# STM32H7B0x register map
File version: 1.3
CPU: CM7 r0p1, little endian, MPU, FPU, 4 interrupt priority bits
Registers are 32-bit, read-write, reset 0x0 unless marked. A register's access mark holds for its fields unless they carry their own. Offsets are from the block's base; [hi:lo] are bit positions; {n}, {i} and the like mark numbered series.

## RCC (part 2 of 3) — Reset and clock control
Base 0x58024400
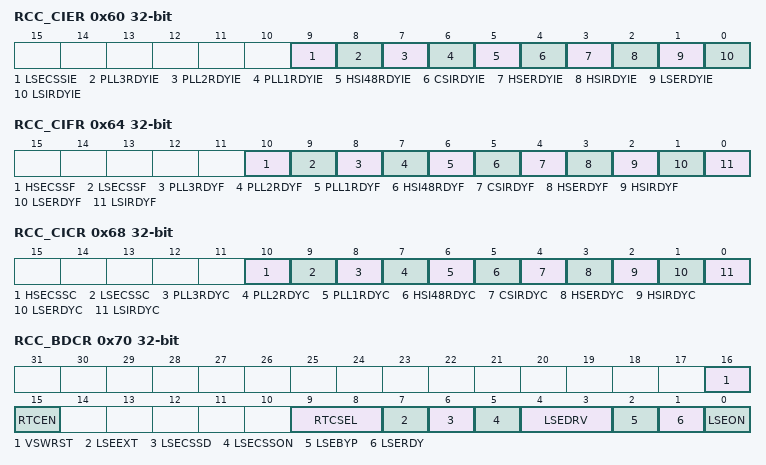
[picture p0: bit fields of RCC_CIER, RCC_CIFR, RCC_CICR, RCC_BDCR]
0x60 RCC_CIER
  [9] LSECSSIE — LSE clock security system interrupt enable Set and reset by software to enable/disable interrupt caused by the clock security system (CSS) on external 32 kHz oscillator.
    0=LSE CSS interrupt disabled (default after reset); 1=LSE CSS interrupt enabled
  [8] PLL3RDYIE — PLL3 ready interrupt enable Set and reset by software to enable/disable interrupt caused by PLL3 lock.
    0=PLL3 lock interrupt disabled (default after reset); 1=PLL3 lock interrupt enabled
  [7] PLL2RDYIE — PLL2 ready interrupt enable Set and reset by software to enable/disable interrupt caused by PLL2 lock.
    0=PLL2 lock interrupt disabled (default after reset); 1=PLL2 lock interrupt enabled
  [6] PLL1RDYIE — PLL1 ready interrupt enable Set and reset by software to enable/disable interrupt caused by PLL1 lock.
    0=PLL1 lock interrupt disabled (default after reset); 1=PLL1 lock interrupt enabled
  [5] HSI48RDYIE — HSI48 ready interrupt enable Set and reset by software to enable/disable interrupt caused by the HSI48 oscillator stabilization.
    0=HSI48 ready interrupt disabled (default after reset); 1=HSI48 ready interrupt enabled
  [4] CSIRDYIE — CSI ready interrupt enable Set and reset by software to enable/disable interrupt caused by the CSI oscillator stabilization.
    0=CSI ready interrupt disabled (default after reset); 1=CSI ready interrupt enabled
  [3] HSERDYIE — HSE ready interrupt enable Set and reset by software to enable/disable interrupt caused by the HSE oscillator stabilization.
    0=HSE ready interrupt disabled (default after reset); 1=HSE ready interrupt enabled
  [2] HSIRDYIE — HSI ready interrupt enable Set and reset by software to enable/disable interrupt caused by the HSI oscillator stabilization.
    0=HSI ready interrupt disabled (default after reset); 1=HSI ready interrupt enabled
  [1] LSERDYIE — LSE ready interrupt enable Set and reset by software to enable/disable interrupt caused by the LSE oscillator stabilization.
    0=LSE ready interrupt disabled (default after reset); 1=LSE ready interrupt enabled
  [0] LSIRDYIE — LSI ready interrupt enable Set and reset by software to enable/disable interrupt caused by the LSI oscillator stabilization.
    0=LSI ready interrupt disabled (default after reset); 1=LSI ready interrupt enabled
0x64 RCC_CIFR ro
  [10] HSECSSF — HSE clock security system interrupt flag Reset by software by writing HSECSSC bit. Set by hardware in case of HSE clock failure.
    0=no clock security interrupt caused by HSE clock failure (default after reset); 1=clock security interrupt caused by HSE clock failure
  [9] LSECSSF — LSE clock security system interrupt flag Reset by software by writing LSECSSC bit. Set by hardware when a failure is detected on the external 32 kHz oscillator and LSECSSIE is set.
    0=no failure detected on the external 32 kHz oscillator (default after reset); 1=failure detected on the external 32 kHz oscillator
  [8] PLL3RDYF — PLL3 ready interrupt flag Reset by software by writing PLL3RDYC bit. Set by hardware when the PLL3 locks and PLL3RDYIE is set.
    0=no clock ready interrupt caused by PLL3 lock (default after reset); 1=clock ready interrupt caused by PLL3 lock
  [7] PLL2RDYF — PLL2 ready interrupt flag Reset by software by writing PLL2RDYC bit. Set by hardware when the PLL2 locks and PLL2RDYIE is set.
    0=no clock ready interrupt caused by PLL2 lock (default after reset); 1=clock ready interrupt caused by PLL2 lock
  [6] PLL1RDYF — PLL1 ready interrupt flag Reset by software by writing PLL1RDYC bit. Set by hardware when the PLL1 locks and PLL1RDYIE is set.
    0=no clock ready interrupt caused by PLL1 lock (default after reset); 1=clock ready interrupt caused by PLL1 lock
  [5] HSI48RDYF — HSI48 ready interrupt flag Reset by software by writing HSI48RDYC bit. Set by hardware when the HSI48 clock becomes stable and HSI48RDYIE is set.
    0=no clock ready interrupt caused by the HSI48 oscillator (default after reset); 1=clock ready interrupt caused by the HSI48 oscillator
  [4] CSIRDYF — CSI ready interrupt flag Reset by software by writing CSIRDYC bit. Set by hardware when the CSI clock becomes stable and CSIRDYIE is set.
    0=no clock ready interrupt caused by the CSI (default after reset); 1=clock ready interrupt caused by the CSI
  [3] HSERDYF — HSE ready interrupt flag Reset by software by writing HSERDYC bit. Set by hardware when the HSE clock becomes stable and HSERDYIE is set.
    0=no clock ready interrupt caused by the HSE (default after reset); 1=clock ready interrupt caused by the HSE
  [2] HSIRDYF — HSI ready interrupt flag Reset by software by writing HSIRDYC bit. Set by hardware when the HSI clock becomes stable and HSIRDYIE is set.
    0=no clock ready interrupt caused by the HSI (default after reset); 1=clock ready interrupt caused by the HSI
  [1] LSERDYF — LSE ready interrupt flag Reset by software by writing LSERDYC bit. Set by hardware when the LSE clock becomes stable and LSERDYIE is set.
    0=no clock ready interrupt caused by the LSE (default after reset); 1=clock ready interrupt caused by the LSE
  [0] LSIRDYF — LSI ready interrupt flag Reset by software by writing LSIRDYC bit. Set by hardware when the LSI clock becomes stable and LSIRDYIE is set.
    0=no clock ready interrupt caused by the LSI (default after reset); 1=clock ready interrupt caused by the LSI
0x68 RCC_CICR
  [10] HSECSSC — HSE clock security system interrupt clear Set by software to clear HSECSSF. Reset by hardware when clear done.
    0=HSECSSF no effect (default after reset); 1=HSECSSF cleared
  [9] LSECSSC — LSE clock security system interrupt clear Set by software to clear LSECSSF. Reset by hardware when clear done.
    0=LSECSSF no effect (default after reset); 1=LSECSSF cleared
  [8] PLL3RDYC — PLL3 ready interrupt clear Set by software to clear PLL3RDYF. Reset by hardware when clear done.
    0=PLL3RDYF no effect (default after reset); 1=PLL3RDYF cleared
  [7] PLL2RDYC — PLL2 ready interrupt clear Set by software to clear PLL2RDYF. Reset by hardware when clear done.
    0=PLL2RDYF no effect (default after reset); 1=PLL2RDYF cleared
  [6] PLL1RDYC — PLL1 ready interrupt clear Set by software to clear PLL1RDYF. Reset by hardware when clear done.
    0=PLL1RDYF no effect (default after reset); 1=PLL1RDYF cleared
  [5] HSI48RDYC — HSI48 ready interrupt clear Set by software to clear HSI48RDYF. Reset by hardware when clear done.
    0=HSI48RDYF no effect (default after reset); 1=HSI48RDYF cleared
  [4] CSIRDYC — CSI ready interrupt clear Set by software to clear CSIRDYF. Reset by hardware when clear done.
    0=CSIRDYF no effect (default after reset); 1=CSIRDYF cleared
  [3] HSERDYC — HSE ready interrupt clear Set by software to clear HSERDYF. Reset by hardware when clear done.
    0=HSERDYF no effect (default after reset); 1=HSERDYF cleared
  [2] HSIRDYC — HSI ready interrupt clear Set by software to clear HSIRDYF. Reset by hardware when clear done.
    0=HSIRDYF no effect (default after reset); 1=HSIRDYF cleared
  [1] LSERDYC — LSE ready interrupt clear Set by software to clear LSERDYF. Reset by hardware when clear done.
    0=LSERDYF no effect (default after reset); 1=LSERDYF cleared
  [0] LSIRDYC — LSI ready interrupt clear Set by software to clear LSIRDYF. Reset by hardware when clear done.
    0=LSIRDYF no effect (default after reset); 1=LSIRDYF cleared
0x70 RCC_BDCR access per field — RCC Backup domain control register
  [16] VSWRST rw — VSwitch domain software reset Set and reset by software.
    0=reset not activated (default after Backup domain reset); 1=resets the entire VSW domain
  [15] RTCEN rw — RTC clock enable Set and reset by software.
    0=rtc_ck disabled (default after Backup domain reset); 1=rtc_ck enabled
  [9:8] RTCSEL rw-once — RTC clock source selection Set by software to select the clock source for the RTC. These bits can be written only one time (except in case of failure detection on LSE). These bits must be written before LSECSSON is enabled. The VSWRST bit can be used to reset them, then it can be written one time again. If HSE is selected as RTC clock, this clock is lost when the system is in Stop mode or in case of a pin reset (NRST).
    0=no clock (default after Backup domain reset); 1=LSE selected as RTC clock; 2=LSI selected as RTC clock; 3=HSE divided by RTCPRE value selected as RTC clock
  [7] LSEEXT rw — low-speed external clock type in Bypass mode Set and reset by software to select the external clock type (analog or digital). The external clock must be enabled with the LSEON bit, to be used by the device. The LSEEXT bit can be written only if the LSE oscillator is disabled.
    0=LSE in analog mode (default after Backup domain reset); 1=LSE in digital mode (do not use if RTC is active)
  [6] LSECSSD ro — LSE clock security system failure detection Set by hardware to indicate when a failure has been detected by the clock security system on the external 32 kHz oscillator.
    0=no failure detected on 32 kHz oscillator (default after Backup domain reset); 1=failure detected on 32 kHz oscillator
  [5] LSECSSON rw — LSE clock security system enable Set by software to enable the clock security system on 32 kHz oscillator. LSECSSON must be enabled after LSE is enabled (LSEON enabled) and ready (LSERDY set by hardware) and after RTCSEL is selected. Once enabled, this bit cannot be disabled, except after a LSE failure detection (LSECSSD = 1). In that case the software must disable LSECSSON.
    0=CSS on 32 kHz oscillator OFF (default after Backup domain reset); 1=CSS on 32 kHz oscillator ON
  [4:3] LSEDRV rw — LSE oscillator driving capability Set by software to select the driving capability of the LSE oscillator.
    0=lowest drive (default after Backup domain reset); 1=medium-low drive; 2=medium-high drive; 3=highest drive
  [2] LSEBYP rw — LSE oscillator bypass Set and reset by software to bypass oscillator in debug mode. This bit must not be written when the LSE is enabled (by LSEON) or ready (LSERDY = 1)
    0=LSE oscillator not bypassed (default after Backup domain reset); 1=LSE oscillator bypassed
  [1] LSERDY ro — LSE oscillator ready Set and reset by hardware to indicate when the LSE is stable. This bit needs 6 cycles of lse_ck clock to fall down after LSEON has been set to 0.
    0=LSE oscillator not ready (default after Backup domain reset); 1=LSE oscillator ready
  [0] LSEON rw — LSE oscillator enabled Set and reset by software.
    0=LSE oscillator OFF (default after Backup domain reset); 1=LSE oscillator ON
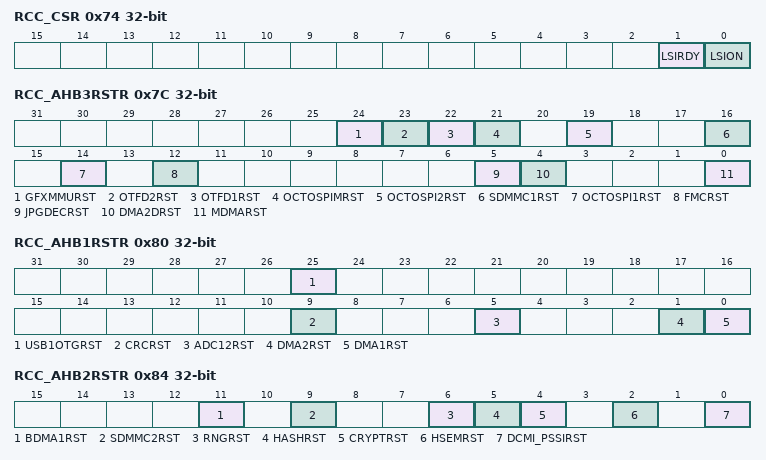
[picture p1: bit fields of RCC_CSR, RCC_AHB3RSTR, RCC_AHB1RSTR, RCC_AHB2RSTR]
0x74 RCC_CSR access per field — RCC clock control and status register
  [1] LSIRDY ro — LSI oscillator ready Set and reset by hardware to indicate when the low-speed internal RC oscillator is stable. This bit needs 3 cycles of lsi_ck clock to fall down after LSION has been set to 0. This bit can be set even when LSION is not enabled if there is a request for LSI clock by the clock security system on LSE or by the low-speed watchdog or by the RTC.
    0=LSI clock is not ready (default after reset); 1=LSI clock is ready
  [0] LSION rw — LSI oscillator enable Set and reset by software.
    0=LSI is OFF (default after reset); 1=LSI is ON
0x7C RCC_AHB3RSTR
  [24] GFXMMURST — GFXMMU reset Set and reset by software
    0=does not reset the GFXMMU (default after reset); 1=resets the GFXMMU
  [23] OTFD2RST — OTFD2 reset Set and reset by software Take care that resetting the OTFD means loosing the decryption key loaded during secure boot.
    0=does not reset the OTFD2 (default after reset); 1=resets the OTFD2
  [22] OTFD1RST — OTFD1 reset Set and reset by software Take care that resetting the OTFD means loosing the decryption key loaded during secure boot.
    0=does not reset the OTFD1 (default after reset); 1=resets the OTFD1
  [21] OCTOSPIMRST — OCTOSPIM reset Set and reset by software
    0=does not reset the OCTOSPIM (default after reset); 1=resets the OCTOSPIM
  [19] OCTOSPI2RST — OCTOSPI2 and OCTOSPI2 delay block reset Set and reset by software
    0=does not reset the OCTOSPI2 and OCTOSPI2 delay block (default after reset); 1=resets the OCTOSPI2 and OCTOSPI2 delay block
  [16] SDMMC1RST — SDMMC1 and SDMMC1 delay blocks reset Set and reset by software.
    0=does not reset SDMMC1 and SDMMC1 delay blocks (default after reset); 1=resets SDMMC1 and SDMMC1 delay blocks
  [14] OCTOSPI1RST — OCTOSPI1 and OCTOSPI1 delay blocks reset Set and reset by software.
    0=does not reset OCTOSPI1 and OCTOSPI1 delay blocks (default after reset); 1=resets OCTOSPI1 and OCTOSPI1 delay blocks
  [12] FMCRST — FMC block reset Set and reset by software.
    0=does not reset FMC block (default after reset); 1=resets FMC block
  [5] JPGDECRST — JPGDEC block reset Set and reset by software.
    0=does not reset JPGDEC block (default after reset); 1=resets JPGDEC block
  [4] DMA2DRST — DMA2D block reset Set and reset by software.
    0=does not reset DMA2D block (default after reset); 1=resets DMA2D block
  [0] MDMARST — MDMA block reset Set and reset by software.
    0=does not reset MDMA block (default after reset); 1=resets MDMA block
0x80 RCC_AHB1RSTR
  [25] USB1OTGRST — USB1OTG block reset Set and reset by software.
    0=does not reset USB1OTG block (default after reset); 1=resets USB1OTG block
  [9] CRCRST — CRC block reset Set and reset by software.
    0=does not reset CRC block (default after reset); 1=resets CRC block
  [5] ADC12RST — ADC1 and 2 blocks reset Set and reset by software.
    0=does not reset ADC1 and 2 blocks (default after reset); 1=resets ADC1 and 2 blocks
  [1] DMA2RST — DMA2 and DMAMUX2 blocks reset Set and reset by software.
    0=does not reset DMA2 and DMAMUX2 blocks (default after reset); 1=resets DMA2 and DMAMUX2 blocks
  [0] DMA1RST — DMA1 and DMAMUX1 blocks reset Set and reset by software.
    0=does not reset DMA1 and DMAMUX1 blocks (default after reset); 1=resets DMA1 and DMAMUX1 blocks
0x84 RCC_AHB2RSTR
  [11] BDMA1RST — BDMA1 reset (DFSDM dedicated DMA) Set and reset by software.
    0=does not reset DMA block (default after reset); 1=resets DMA block
  [9] SDMMC2RST — SDMMC2 and SDMMC2 delay blocks reset Set and reset by software.
    0=does not reset SDMMC2 and SDMMC2 delay blocks (default after reset); 1=resets SDMMC2 and SDMMC2 delay blocks
  [6] RNGRST — random number generator block reset Set and reset by software.
    0=does not reset RNG block (default after reset); 1=resets RNG block
  [5] HASHRST — hash block reset Set and reset by software.
    0=does not reset hash block (default after reset); 1=resets hash block
  [4] CRYPTRST — cryptography block reset Set and reset by software.
    0=does not reset cryptography block (default after reset); 1=resets cryptography block
  [2] HSEMRST — HSEM block reset Set and reset by software.
    0=does not reset HSEM block (default after reset); 1=resets HSEM block
  [0] DCMI_PSSIRST — digital camera interface block reset (DCMI or PSSI depending which IP is active) Set and reset by software.
    0=does not reset the DCMI/PSSI block (default after reset); 1=resets the DCMI/PSSI block
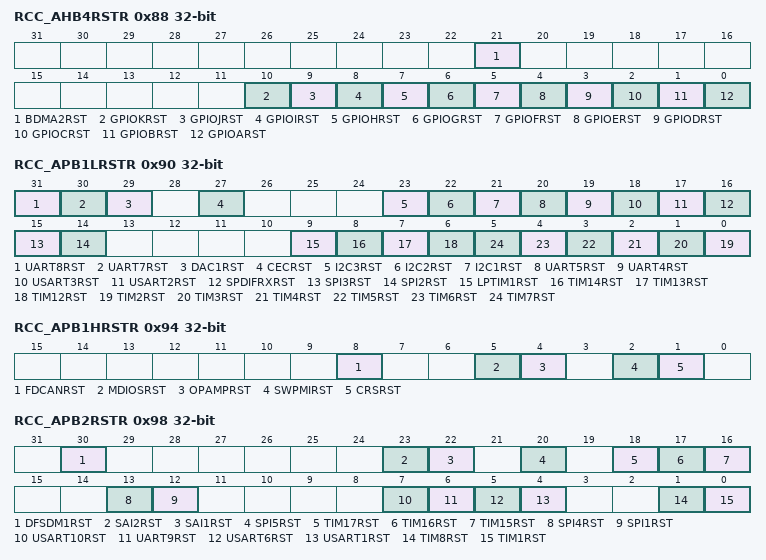
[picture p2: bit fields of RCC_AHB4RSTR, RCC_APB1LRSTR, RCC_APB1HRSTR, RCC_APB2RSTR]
0x88 RCC_AHB4RSTR
  [21] BDMA2RST — SmartRun domain DMA and DMAMUX blocks reset Set and reset by software.
    0=does not reset the DMA and DMAMUX blocks (default after reset); 1=resets the DMA and DMAMUX blocks
  [10] GPIOKRST — GPIOK block reset Set and reset by software.
    0=does not reset the GPIOK block (default after reset); 1=resets the GPIOK block
  [9] GPIOJRST — GPIOJ block reset Set and reset by software.
    0=does not reset the GPIOJ block (default after reset); 1=resets the GPIOJ block
  [8] GPIOIRST — GPIOI block reset Set and reset by software.
    0=does not reset the GPIOI block (default after reset); 1=resets the GPIOI block
  [7] GPIOHRST — GPIOH block reset Set and reset by software.
    0=does not reset the GPIOH block (default after reset); 1=resets the GPIOH block
  [6] GPIOGRST — GPIOG block reset Set and reset by software.
    0=does not reset the GPIOG block (default after reset); 1=resets the GPIOG block
  [5] GPIOFRST — GPIOF block reset Set and reset by software.
    0=does not reset the GPIOF block (default after reset); 1=resets the GPIOF block
  [4] GPIOERST — GPIOE block reset Set and reset by software.
    0=does not reset the GPIOE block (default after reset); 1=resets the GPIOE block
  [3] GPIODRST — GPIOD block reset Set and reset by software.
    0=does not reset the GPIOD block (default after reset); 1=resets the GPIOD block
  [2] GPIOCRST — GPIOC block reset Set and reset by software.
    0=does not reset the GPIOC block (default after reset); 1=resets the GPIOC block
  [1] GPIOBRST — GPIOB block reset Set and reset by software.
    0=does not reset the GPIOB block (default after reset); 1=resets the GPIOB block
  [0] GPIOARST — GPIOA block reset Set and reset by software.
    0=does not reset the GPIOA block (default after reset); 1=resets the GPIOA block
0x8C RCC_APB3RSTR
  [3] LTDCRST — LTDC block reset Set and reset by software.
    0=does not reset the LTDC block (default after reset); 1=resets the LTDC block
0x90 RCC_APB1LRSTR
  [31] UART8RST — UART8 block reset Set and reset by software.
    0=does not reset the UART8 block (default after reset); 1=resets the UART8 block
  [30] UART7RST — UART7 block reset Set and reset by software.
    0=does not reset the UART7 block (default after reset); 1=resets the UART7 block
  [29] DAC1RST — DAC1 (containing two converters) reset Set and reset by software.
    0=does not reset the DAC1 (default after reset); 1=resets the DAC1
  [27] CECRST — HDMI-CEC block reset Set and reset by software.
    0=does not reset the HDMI-CEC block (default after reset); 1=resets the HDMI-CEC block
  [23] I2C3RST — I2C3 block reset Set and reset by software.
    0=does not reset the I2C3 block (default after reset); 1=resets the I2C3 block
  [22] I2C2RST — I2C2 block reset Set and reset by software.
    0=does not reset the I2C2 block (default after reset); 1=resets the I2C2 block
  [21] I2C1RST — I2C1 block reset Set and reset by software.
    0=does not reset the I2C1 block (default after reset); 1=resets the I2C1 block
  [20] UART5RST — UART5 block reset Set and reset by software.
    0=does not reset the UART5 block (default after reset); 1=resets the UART5 block
  [19] UART4RST — UART4 block reset Set and reset by software.
    0=does not reset the UART4 block (default after reset); 1=resets the UART4 block
  [18] USART3RST — USART3 block reset Set and reset by software.
    0=does not reset the USART3 block (default after reset); 1=resets the USART3 block
  [17] USART2RST — USART2 block reset Set and reset by software.
    0=does not reset the USART2 block (default after reset); 1=resets the USART2 block
  [16] SPDIFRXRST — SPDIFRX block reset Set and reset by software.
    0=does not reset the SPDIFRX block (default after reset); 1=resets the SPDIFRX block
  [15] SPI3RST — SPI3 block reset Set and reset by software.
    0=does not reset the SPI3 block (default after reset); 1=resets the SPI3 block
  [14] SPI2RST — SPI2 block reset Set and reset by software.
    0=does not reset the SPI2 block (default after reset); 1=resets the SPI2 block
  [9] LPTIM1RST — LPTIM1 block reset Set and reset by software.
    0=does not reset the LPTIM1 block (default after reset); 1=resets the LPTIM1 block
  [8] TIM14RST — TIM14 block reset Set and reset by software.
    0=does not reset the TIM14 block (default after reset); 1=resets the TIM14 block
  [7] TIM13RST — TIM13 block reset Set and reset by software.
    0=does not reset the TIM13 block (default after reset); 1=resets the TIM13 block
  [6] TIM12RST — TIM12 block reset Set and reset by software.
    0=does not reset the TIM12 block (default after reset); 1=resets the TIM12 block
  [n-2] TIM{n}RST (n=2..7) — TIM{n} block reset Set and reset by software.
    0=does not reset the TIM{n} block (default after reset); 1=resets the TIM{n} block
0x94 RCC_APB1HRSTR
  [8] FDCANRST — FDCAN block reset Set and reset by software.
    0=does not reset the FDCAN block (default after reset); 1=resets the FDCAN block
  [5] MDIOSRST — MDIOS block reset Set and reset by software.
    0=does not reset the MDIOS block (default after reset); 1=resets the MDIOS block
  [4] OPAMPRST — OPAMP block reset Set and reset by software.
    0=does not reset the OPAMP block (default after reset); 1=resets the OPAMP block
  [2] SWPMIRST — SWPMI block reset Set and reset by software.
    0=does not reset the SWPMI block (default after reset); 1=resets the SWPMI block
  [1] CRSRST — clock recovery system reset Set and reset by software.
    0=does not reset CRS (default after reset); 1=resets CRS
0x98 RCC_APB2RSTR
  [30] DFSDM1RST — DFSDM1 block reset Set and reset by software.
    0=does not reset DFSDM1 block (default after reset); 1=resets DFSDM1 block
  [23] SAI2RST — SAI2 block reset Set and reset by software.
    0=does not reset the SAI2 block (default after reset); 1=resets the SAI2 block
  [22] SAI1RST — SAI1 block reset Set and reset by software.
    0=does not reset the SAI1 (default after reset); 1=resets the SAI1
  [20] SPI5RST — SPI5 block reset Set and reset by software.
    0=does not reset the SPI5 block (default after reset); 1=resets the SPI5 block
  [18] TIM17RST — TIM17 block reset Set and reset by software.
    0=does not reset the TIM17 block (default after reset); 1=resets the TIM17 block
  [17] TIM16RST — TIM16 block reset Set and reset by software.
    0=does not reset the TIM16 block (default after reset); 1=resets the TIM16 block
  [16] TIM15RST — TIM15 block reset Set and reset by software.
    0=does not reset the TIM15 block (default after reset); 1=resets the TIM15 block
  [13] SPI4RST — SPI4 block reset Set and reset by software.
    0=does not reset the SPI4 block (default after reset); 1=resets the SPI4 block
  [12] SPI1RST — SPI1 block reset Set and reset by software.
    0=does not reset the SPI1 block (default after reset); 1=resets the SPI1 block
  [7] USART10RST — USART10 block reset Set and reset by software.
    0=does not reset the USART10 block (default after reset); 1=resets the USART10 block
  [6] UART9RST — UART9 block reset Set and reset by software.
    0=does not reset the UART9 block (default after reset); 1=resets the UART9 block
  [5] USART6RST — USART6 block reset Set and reset by software.
    0=does not reset the USART6 block (default after reset); 1=resets the USART6 block
  [4] USART1RST — USART1 block reset Set and reset by software.
    0=does not reset the USART1 block (default after reset); 1=resets the USART1 block
  [1] TIM8RST — TIM8 block reset Set and reset by software.
    0=does not reset the TIM8 block (default after reset); 1=resets the TIM8 block
  [0] TIM1RST — TIM1 block reset Set and reset by software.
    0=does not reset the TIM1 block (default after reset); 1=resets the TIM1 block
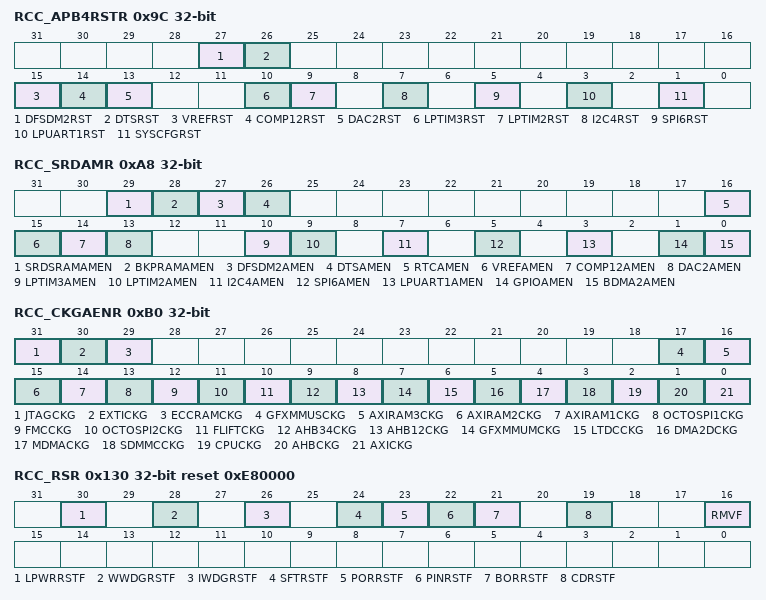
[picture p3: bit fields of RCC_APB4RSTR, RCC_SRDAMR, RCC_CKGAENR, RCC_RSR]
0x9C RCC_APB4RSTR
  [27] DFSDM2RST — DFSDM2 block reset Set and reset by software.
    0=does not reset the DFSDM2 block (default after reset); 1=resets the DFSDM2 block
  [26] DTSRST — Digital temperature sensor block reset Set and reset by software.
    0=does not reset the DTS block (default after reset); 1=resets the DTS block
  [15] VREFRST — VREF block reset Set and reset by software.
    0=does not reset the VREF block (default after reset); 1=resets the VREF block
  [14] COMP12RST — COMP1 and 2 blocks reset Set and reset by software.
    0=does not reset the COMP1 and 2 blocks (default after reset); 1=resets the COMP1 and 2 blocks
  [13] DAC2RST — DAC2 (containing one converter) reset Set and reset by software.
    0=does not reset the DAC2 (default after reset); 1=resets the DAC2
  [10] LPTIM3RST — LPTIM3 block reset Set and reset by software.
    0=does not reset the LPTIM3 block (default after reset); 1=resets the LPTIM3 block
  [9] LPTIM2RST — LPTIM2 block reset Set and reset by software.
    0=does not reset the LPTIM2 block (default after reset); 1=resets the LPTIM2 block
  [7] I2C4RST — I2C4 block reset Set and reset by software.
    0=does not reset the I2C4 block (default after reset); 1=resets the I2C4 block
  [5] SPI6RST — SPI6 block reset Set and reset by software.
    0=does not reset the SPI6 block (default after reset); 1=resets the SPI6 block
  [3] LPUART1RST — LPUART1 block reset Set and reset by software.
    0=does not reset the LPUART1 block (default after reset); 1=resets the LPUART1 block
  [1] SYSCFGRST — SYSCFG block reset Set and reset by software.
    0=does not reset the SYSCFG block (default after reset); 1=resets the SYSCFG block
0xA8 RCC_SRDAMR — RCC SmartRun domain Autonomous mode register
  [29] SRDSRAMAMEN — SmartRun domain SRAM Autonomous mode enable Set and reset by software. Refer to for additional information.
    0=SRDSRAM clock disabled when the CPU is in CStop (default after reset); 1=SRDSRAM bus clock enabled when the SmartRun domain is in Run
  [28] BKPRAMAMEN — Backup RAM Autonomous mode enable Set and reset by software. Refer to for additional information.
    0=Backup RAM clock disabled when the CPU is in CStop (default after reset); 1=Backup RAM clock enabling is controlled by the SmartRun domain state
  [27] DFSDM2AMEN — DFSDM2 Autonomous mode enable Set and reset by software. Refer to for additional information.
    0=DFSDM2 clock disabled when the CPU is in CStop (default after reset); 1=DFSDM2 peripheral clocks enabled when the SmartRun domain is in Run mode. Kernel clock enabled when the SmartRun domain is in Stop mode.
  [26] DTSAMEN — Digital temperature sensor Autonomous mode enable Set and reset by software. Refer to for additional information.
    0=DTS clocks disabled when the CPU is in CStop (default after reset); 1=DTS clocks enabled when the SmartRun domain is in Run
  [16] RTCAMEN — RTC Autonomous mode enable Set and reset by software. Refer to for additional information.
    0=RTC bus clocks disabled when the CPU is in CStop (default after reset); 1=RTC bus clocks enabled when the SmartRun domain is in Run
  [15] VREFAMEN — VREF Autonomous mode enable Set and reset by software. Refer to for additional information.
    0=VREF clocks disabled when the CPU is in CStop (default after reset); 1=VREF clocks enabled when the SmartRun domain is in Run or Stop mode
  [14] COMP12AMEN — COMP1 and 2 Autonomous mode enable Set and reset by software. Refer to for additional information.
    0=COMP1 and 2 peripheral clocks disabled when the CPU is in CStop (default after reset); 1=COMP1 and 2 peripheral clocks enabled when the SmartRun domain is in Run
  [13] DAC2AMEN — DAC2 (containing one converter) Autonomous mode enable Set and reset by software. Refer to for additional information.
    0=DAC2 peripheral clocks disabled when the CPU is in CStop (default after reset); 1=DAC2 peripheral clocks enabled when the SmartRun domain is in Run
  [10] LPTIM3AMEN — LPTIM3 Autonomous mode enable Set and reset by software. Refer to for additional information.
    0=LPTIM3 peripheral clocks disabled when the CPU is in CStop (default after reset); 1=LPTIM3 peripheral clocks enabled when the SmartRun domain is in Run mode. Kernel clock is enabled when the SmartRun domain is in Stop mode.
  [9] LPTIM2AMEN — LPTIM2 Autonomous mode enable Set and reset by software. Refer to for additional information
    0=LPTIM2 peripheral clocks are disabled when the CPU is in CStop (default after reset); 1=LPTIM2 peripheral clocks enabled when the SmartRun domain is in Run mode. Kernel clock is enabled when the SmartRun domain is in Stop mode.
  [7] I2C4AMEN — I2C4 Autonomous mode enable Set and reset by software. Refer to for additional information.
    0=I2C4 peripheral clocks disabled when the CPU is in CStop (default after reset); 1=I2C4 peripheral clocks enabled when the SmartRun domain is in Run mode. Kernel clock is enabled when the SmartRun domain is in Stop mode.
  [5] SPI6AMEN — SPI6 Autonomous mode enable Set and reset by software. Refer to for additional information.
    0=SPI6 peripheral clocks disabled when the CPU is in CStop (default after reset); 1=SPI6 peripheral clocks enabled when the SmartRun domain is in Run mode. Kernel clock is enabled when the SmartRun domain is in Stop mode.
  [3] LPUART1AMEN — LPUART1 Autonomous mode enable Set and reset by software. Refer to for additional information.
    0=LPUART1 peripheral clocks disabled when the CPU is in CStop (default after reset); 1=LPUART1 peripheral clocks enabled when the SmartRun domain is in Run mode. Kernel clock is enabled when the SmartRun domain is in Stop mode.
  [1] GPIOAMEN — GPIO Autonomous mode enable Set and reset by software. Refer to for additional information.
    0=GPIO peripheral clocks disabled when the CPU is in CStop (default after reset); 1=GPIO peripheral clocks enabled when the SmartRun domain is in Run
  [0] BDMA2AMEN — SmartRun domain DMA and DMAMUX Autonomous mode enable Set and reset by software. Refer to for additional information.
    0=BDMA2 and DMAMUX2 peripheral clocks disabled when the CPU is in CStop (default after reset); 1=BDMA2 and DMAMUX2 peripheral clocks enabled when the SmartRun domain is in Run
0xB0 RCC_CKGAENR — RCC AXI clocks gating enable register
  [31] JTAGCKG — JTAG automatic clock gating This bit is set and reset by software.
    0=The clock gating is disabled. The clock is always enabled.; 1=The clock gating is enabled. The clock is disabled except if a JTAG connection has been detected
  [30] EXTICKG — EXTI clock gating This bit is set and reset by software.
    0=The clock gating is disabled. The clock is always enabled.; 1=The clock gating is enabled. The clock is enabled after an event detection and stopped again when the event flag is cleared.
  [29] ECCRAMCKG — RAM error code correction (ECC) clock gating This bit is set and reset by software.
    0=The clock gating is disabled. The clock is always enabled.; 1=The clock gating is enabled. The ECC clock is enabled only during a RAM access.
  [17] GFXMMUSCKG — AXI matrix slave GFXMMU clock gating This bit is set and reset by software.
    0=The clock gating is disabled. The clock is always enabled; 1=The clock gating is enabled. The AXI matrix slave GFXMMU clock is enabled on bus transaction request.
  [16] AXIRAM3CKG — AXI matrix slave SRAM3 clock gating This bit is set and reset by software.
    0=The clock gating is disabled. The clock is always enabled.; 1=The clock gating is enabled. The AXI matrix slave SRAM3 clock is enabled on bus transaction request.
  [15] AXIRAM2CKG — AXI matrix slave SRAM2 clock gating This bit is set and reset by software.
    0=The clock gating is disabled. The clock is always enabled.; 1=The clock gating is enabled. The AXI matrix slave SRAM2 clock is enabled on bus transaction request.
  [14] AXIRAM1CKG — AXI slave SRAM1 clock gating This bit is set and reset by software.
    0=The clock gating is disabled. The clock is always enabled.; 1=The clock gating is enabled. The AXI matrix slave SRAM1 clock is enabled on bus transaction request.
  [13] OCTOSPI1CKG — AXI slave OCTOSPI1 clock gating This bit is set and reset by software.
    0=The clock gating is disabled. The clock is always enabled.; 1=The clock gating is enabled. The AXI matrix slave OCTOSPI1 clock is enabled on bus transaction request.
  [12] FMCCKG — AXI slave FMC clock gating This bit is set and reset by software.
    0=The clock gating is disabled. The clock is always enabled.; 1=The clock gating is enabled. The AXI matrix slave FMC clock is enabled on bus transaction request.
  [11] OCTOSPI2CKG — AXI slave OCTOSPI2 clock gating This bit is set and reset by software.
    0=The clock gating is disabled. The clock is always enabled.; 1=The clock gating is enabled. The AXI matrix slave OCTOSPI2 clock is enabled on bus transaction request.
  [10] FLIFTCKG — AXI slave Flash interface (FLIFT) clock gating This bit is set and reset by software.
    0=The clock gating is disabled. The clock is always enabled.; 1=The clock gating is enabled. The AXI matrix slave FLIFT clock is enabled on bus transaction request.
  [9] AHB34CKG — AXI slave AHB34 clock gating This bit is set and reset by software.
    0=The clock gating is disabled. The clock is always enabled; 1=The clock gating is enabled. The AXI matrix slave AHB34 clock is enabled on bus transaction request.
  [8] AHB12CKG — AXI slave AHB12 clock gating This bit is set and reset by software.
    0=The clock gating is disabled. The clock is always enabled; 1=The clock gating is enabled. The AXI matrix slave AHB12 clock is enabled on bus transaction request.
  [7] GFXMMUMCKG — AXI master GFXMMU clock gating This bit is set and reset by software.
    0=The clock gating is disabled. The clock is always enabled; 1=The clock gating is enabled. The AXI matrix master GFXMMU clock is enabled on bus transaction request.
  [6] LTDCCKG — AXI master LTDC clock gating This bit is set and reset by software.
    0=The clock gating is disabled. The clock is always enabled.; 1=The clock gating is enabled. The AXI matrix master LTDC clock is enabled on bus transaction request.
  [5] DMA2DCKG — AXI master DMA2D clock gating This bit is set and reset by software.
    0=The clock gating is disabled. The clock is always enabled; 1=The clock gating is enabled. The AXI matrix master DMA2D clock is enabled on bus transaction request.
  [4] MDMACKG — AXI master MDMA clock gating This bit is set and reset by software.
    0=The clock gating is disabled. The clock is always enabled; 1=The clock gating is enabled. The AXI matrix master MDMA clock is enabled on bus transaction request.
  [3] SDMMCCKG — AXI master SDMMC clock gating This bit is set and reset by software.
    0=The clock gating is disabled. The clock is always enabled.; 1=The clock gating is enabled. The AXI matrix master SDMMC clock is enabled on bus transaction request.
  [2] CPUCKG — AXI master CPU clock gating This bit is set and reset by software.
    0=The clock gating is disabled. The clock is always enabled.; 1=The clock gating is enabled. The AXI matrix master CPU clock is enabled on bus transaction request.
  [1] AHBCKG — AXI master AHB clock gating This bit is set and reset by software.
    0=The clock gating is disabled. The clock is always enabled.; 1=The clock gating is enabled. The AXI matrix master AHB clock is enabled on bus transaction request.
  [0] AXICKG — AXI interconnect matrix clock gating This bit is set and reset by software.
    0=The clock gating is disabled. The clock is always enabled; 1=The clock gating is enabled. The AXI interconnect matrix clock is enabled on bus transaction request.
0x130 RCC_RSR access per field reset 0xE80000 — RCC reset status register
  [30] LPWRRSTF ro — reset due to illegal CD DStop or CD DStop2 or CPU CStop flag Reset by software by writing the RMVF bit. Set by hardware when the CPU domain goes erroneously in DStop or DStop2, or when the CPU goes erroneously in CStop.
    0=no illegal reset occurred (default after power-on reset); 1=illegal CD DStop or CD DStop2 or CPU CStop reset occurred
  [28] WWDGRSTF ro — window watchdog reset flag Reset by software by writing the RMVF bit. Set by hardware when a window watchdog reset occurs.
    0=no window watchdog reset occurred from WWDG (default after power-on reset); 1=window watchdog reset occurred from WWDG
  [26] IWDGRSTF ro — independent watchdog reset flag Reset by software by writing the RMVF bit. Set by hardware when an independent watchdog reset occurs.
    0=no independent watchdog reset occurred (default after power-on reset); 1=independent watchdog reset occurred
  [24] SFTRSTF ro — system reset from CPU reset flag Reset by software by writing the RMVF bit. Set by hardware when the system reset is due to CPU.The CPU can generate a system reset by writing SYSRESETREQ bit of AIRCR register of the core M7.
    0=no CPU software reset occurred (default after power-on reset); 1=a system reset has been generated by the CPU
  [23] PORRSTF ro — POR/PDR reset flag Reset by software by writing the RMVF bit. Set by hardware when a POR/PDR reset occurs.
    0=no POR/PDR reset occurred; 1=POR/PDR reset occurred (default after power-on reset)
  [22] PINRSTF ro — pin reset flag (NRST) Reset by software by writing the RMVF bit. Set by hardware when a reset from pin occurs.
    0=no reset from pin occurred; 1=reset from pin occurred (default after power-on reset)
  [21] BORRSTF ro — BOR reset flag Reset by software by writing the RMVF bit. Set by hardware when a BOR reset occurs (pwr_bor_rst).
    0=no BOR reset occurred; 1=BOR reset occurred (default after power-on reset)
  [19] CDRSTF ro — CPU domain power-switch reset flag Reset by software by writing the RMVF bit. Set by hardware when a the CPU domain exits from DStop or after of power-on reset. Set also when the CPU domain exists DStop2 but only when a pad reset has occurred during DStop2 (PINRST bit also set by hardware)
    0=no CPU domain power-switch reset occurred; 1=CPU domain power-switch (ePOD2) reset occurred (default after power-on reset)
  [16] RMVF rw — remove reset flag Set and reset by software to reset the value of the reset flags.
    0=reset of the reset flags not activated (default after power-on reset); 1=resets the value of the reset flags
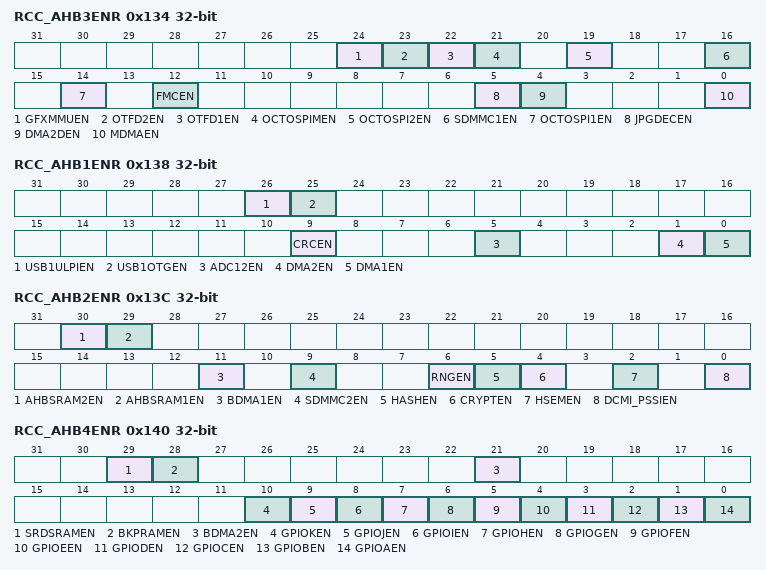
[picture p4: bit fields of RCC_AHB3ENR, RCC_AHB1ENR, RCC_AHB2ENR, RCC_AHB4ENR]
0x134 RCC_AHB3ENR
  [24] GFXMMUEN — GFXMMU clock enable Set and reset by software.
    0=GFXMMU clock disabled (default after reset); 1=GFXMMU clock enabled
  [23] OTFD2EN — OTFD2 clock enable Set and reset by software.
    0=OTFD2 clock disabled (default after reset); 1=OTFD2 clock enabled
  [22] OTFD1EN — OTFD1 clock enable Set and reset by software.
    0=OTFD1 clock disabled (default after reset); 1=OTFD1 clock enabled
  [21] OCTOSPIMEN — OCTOSPIM clock enable Set and reset by software.
    0=OCTOSPIM clock disabled (default after reset); 1=OCTOSPIM clock enabled
  [19] OCTOSPI2EN — OCTOSPI2 clock enable Set and reset by software.
    0=OCTOSPI2 and OCTOSPI2 delay clock disabled (default after reset); 1=OCTOSPI2 OCTOSPI2 delay clock enabled
  [16] SDMMC1EN — SDMMC1 and SDMMC1 delay clock enable Set and reset by software.
    0=SDMMC1 and SDMMC1 delay clock disabled (default after reset); 1=SDMMC1 and SDMMC1 delay clock enabled
  [14] OCTOSPI1EN — OCTOSPI1 and OCTOSPI1 delay clock enable Set and reset by software.
    0=OCTOSPI1 and OCTOSPI1 delay clock disabled (default after reset); 1=OCTOSPI1 and OCTOSPI1 delay clock enabled
  [12] FMCEN — FMC peripheral clocks enable Set and reset by software. The peripheral clocks of the FMC are the kernel clock selected by FMCSEL and provided to fmc_ker_ck input, and the rcc_hclk3 bus interface clock.
    0=FMC peripheral clocks disabled (default after reset); 1=FMC peripheral clocks enabled
  [5] JPGDECEN — JPGDEC peripheral clock enable Set and reset by software.
    0=JPGDEC peripheral clock disabled (default after reset); 1=JPGDEC peripheral clock enabled
  [4] DMA2DEN — DMA2D peripheral clock enable Set and reset by software.
    0=DMA2D peripheral clock disabled (default after reset); 1=DMA2D peripheral clock enabled
  [0] MDMAEN — MDMA peripheral clock enable Set and reset by software.
    0=MDMA peripheral clock disabled (default after reset); 1=MDMA peripheral clock enabled
0x138 RCC_AHB1ENR
  [26] USB1ULPIEN — USB_PHY1 clocks enable Set and reset by software.
    0=USB1ULPI PHY clocks disabled (default after reset); 1=USB1ULPI PHY clocks enabled
  [25] USB1OTGEN — USB1OTG peripheral clocks enable Set and reset by software. The peripheral clocks of the USB1OTG are the kernel clock selected by USBSEL and the rcc_hclk1 bus interface clock.
    0=USB1OTG peripheral clocks disabled (default after reset); 1=USB1OTG peripheral clocks enabled
  [9] CRCEN — CRC peripheral clock enable Set and reset by software.
    0=CRC peripheral clock disabled (default after reset); 1=CRC peripheral clock enabled
  [5] ADC12EN — ADC1 and 2 peripheral clocks enable Set and reset by software. The peripheral clocks of the ADC1 and 2 are the kernel clock selected by ADCSEL and provided to adc_ker_ck input, and the rcc_hclk1 bus interface clock.
    0=ADC1 and 2 peripheral clocks disabled (default after reset); 1=ADC1 and 2 peripheral clocks enabled
  [1] DMA2EN — DMA2 clock enable Set and reset by software.
    0=DMA2 clock disabled (default after reset); 1=DMA2 clock enabled
  [0] DMA1EN — DMA1 clock enable Set and reset by software.
    0=DMA1 clock disabled (default after reset); 1=DMA1 clock enabled
0x13C RCC_AHB2ENR
  [30] AHBSRAM2EN — AHBSRAM2 block enable Set and reset by software. When set, this bit indicates that the SRAM2 is allocated by the CPU. It causes the CPU domain to take into account also the CPU operation modes, keeping the CPU domain in DRun when the CPU is in CRun.
    0=AHBSRAM2 interface clock is disabled. (default after reset); 1=AHBSRAM2 interface clock is enabled
  [29] AHBSRAM1EN — AHBSRAM1 block enable Set and reset by software. When set, this bit indicates that the SRAM1 is allocated by the CPU. It causes the CPU domain to take into account also the CPU operation modes, keeping the CPU domain in DRun when the CPU is in CRun.
    0=AHBSRAM1 interface clock is disabled. (default after reset); 1=AHBSRAM1 interface clock is enabled
  [11] BDMA1EN — DMA clock enable (DFSDM dedicated DMA) Set and reset by software.
    0=DMA clock disabled (default after reset); 1=DMA clock enabled
  [9] SDMMC2EN — SDMMC2 and SDMMC2 delay clock enable Set and reset by software.
    0=SDMMC2 and SDMMC2 delay clock disabled (default after reset); 1=SDMMC2 and SDMMC2 delay clock enabled
  [6] RNGEN — RNG peripheral clocks enable Set and reset by software. The peripheral clocks of the RNG are the kernel clock selected by RNGSEL and provided to rng_clk input, and the rcc_hclk2 bus interface clock.
    0=RNG peripheral clocks disabled (default after reset); 1=RNG peripheral clocks enabled:
  [5] HASHEN — HASH peripheral clock enable Set and reset by software.
    0=HASH peripheral clock disabled (default after reset); 1=HASH peripheral clock enabled
  [4] CRYPTEN — CRYPT peripheral clock enable Set and reset by software.
    0=CRYPT peripheral clock disabled (default after reset); 1=CRYPT peripheral clock enabled
  [2] HSEMEN — HSEM peripheral clock enable Set and reset by software.
    0=HSEM peripheral clock disabled (default after reset); 1=HSEM peripheral clock enabled
  [0] DCMI_PSSIEN — digital camera interface peripheral clock enable (DCMI or PSSI depending which IP is active) Set and reset by software.
    0=DCMI/PSSI peripheral clock disabled (default after reset); 1=DCMI/PSSI peripheral clock enabled
0x140 RCC_AHB4ENR
  [29] SRDSRAMEN — SmartRun domain SRAM clock enable Set and reset by software.
    0=SRDSRAM clock disabled (default after reset); 1=SRDSRAM clock enabled
  [28] BKPRAMEN — Backup RAM clock enable Set and reset by software.
    0=Backup RAM clock disabled (default after reset); 1=Backup RAM clock enabled
  [21] BDMA2EN — SmartRun domain DMA and DMAMUX clock enable Set and reset by software.
    0=BDMA2 and DMAMUX2 clock disabled (default after reset); 1=BDMA2 and DMAMUX2 clock enabled
  [10] GPIOKEN — GPIOK peripheral clock enable Set and reset by software.
    0=GPIOK peripheral clock disabled (default after reset); 1=GPIOK peripheral clock enabled
  [9] GPIOJEN — GPIOJ peripheral clock enable Set and reset by software.
    0=GPIOJ peripheral clock disabled (default after reset); 1=GPIOJ peripheral clock enabled
  [8] GPIOIEN — GPIOI peripheral clock enable Set and reset by software.
    0=GPIOI peripheral clock disabled (default after reset); 1=GPIOI peripheral clock enabled
  [7] GPIOHEN — GPIOH peripheral clock enable Set and reset by software.
    0=GPIOH peripheral clock disabled (default after reset); 1=GPIOH peripheral clock enabled
  [6] GPIOGEN — GPIOG peripheral clock enable Set and reset by software.
    0=GPIOG peripheral clock disabled (default after reset); 1=GPIOG peripheral clock enabled
  [5] GPIOFEN — GPIOF peripheral clock enable Set and reset by software.
    0=GPIOF peripheral clock disabled (default after reset); 1=GPIOF peripheral clock enabled
  [4] GPIOEEN — GPIOE peripheral clock enable Set and reset by software.
    0=GPIOE peripheral clock disabled (default after reset); 1=GPIOE peripheral clock enabled
  [3] GPIODEN — GPIOD peripheral clock enable Set and reset by software.
    0=GPIOD peripheral clock disabled (default after reset); 1=GPIOD peripheral clock enabled
  [2] GPIOCEN — GPIOC peripheral clock enable Set and reset by software.
    0=GPIOC peripheral clock disabled (default after reset); 1=GPIOC peripheral clock enabled
  [1] GPIOBEN — GPIOB peripheral clock enable Set and reset by software.
    0=GPIOB peripheral clock disabled (default after reset); 1=GPIOB peripheral clock enabled
  [0] GPIOAEN — GPIOA peripheral clock enable Set and reset by software.
    0=GPIOA peripheral clock disabled (default after reset); 1=GPIOA peripheral clock enabled
